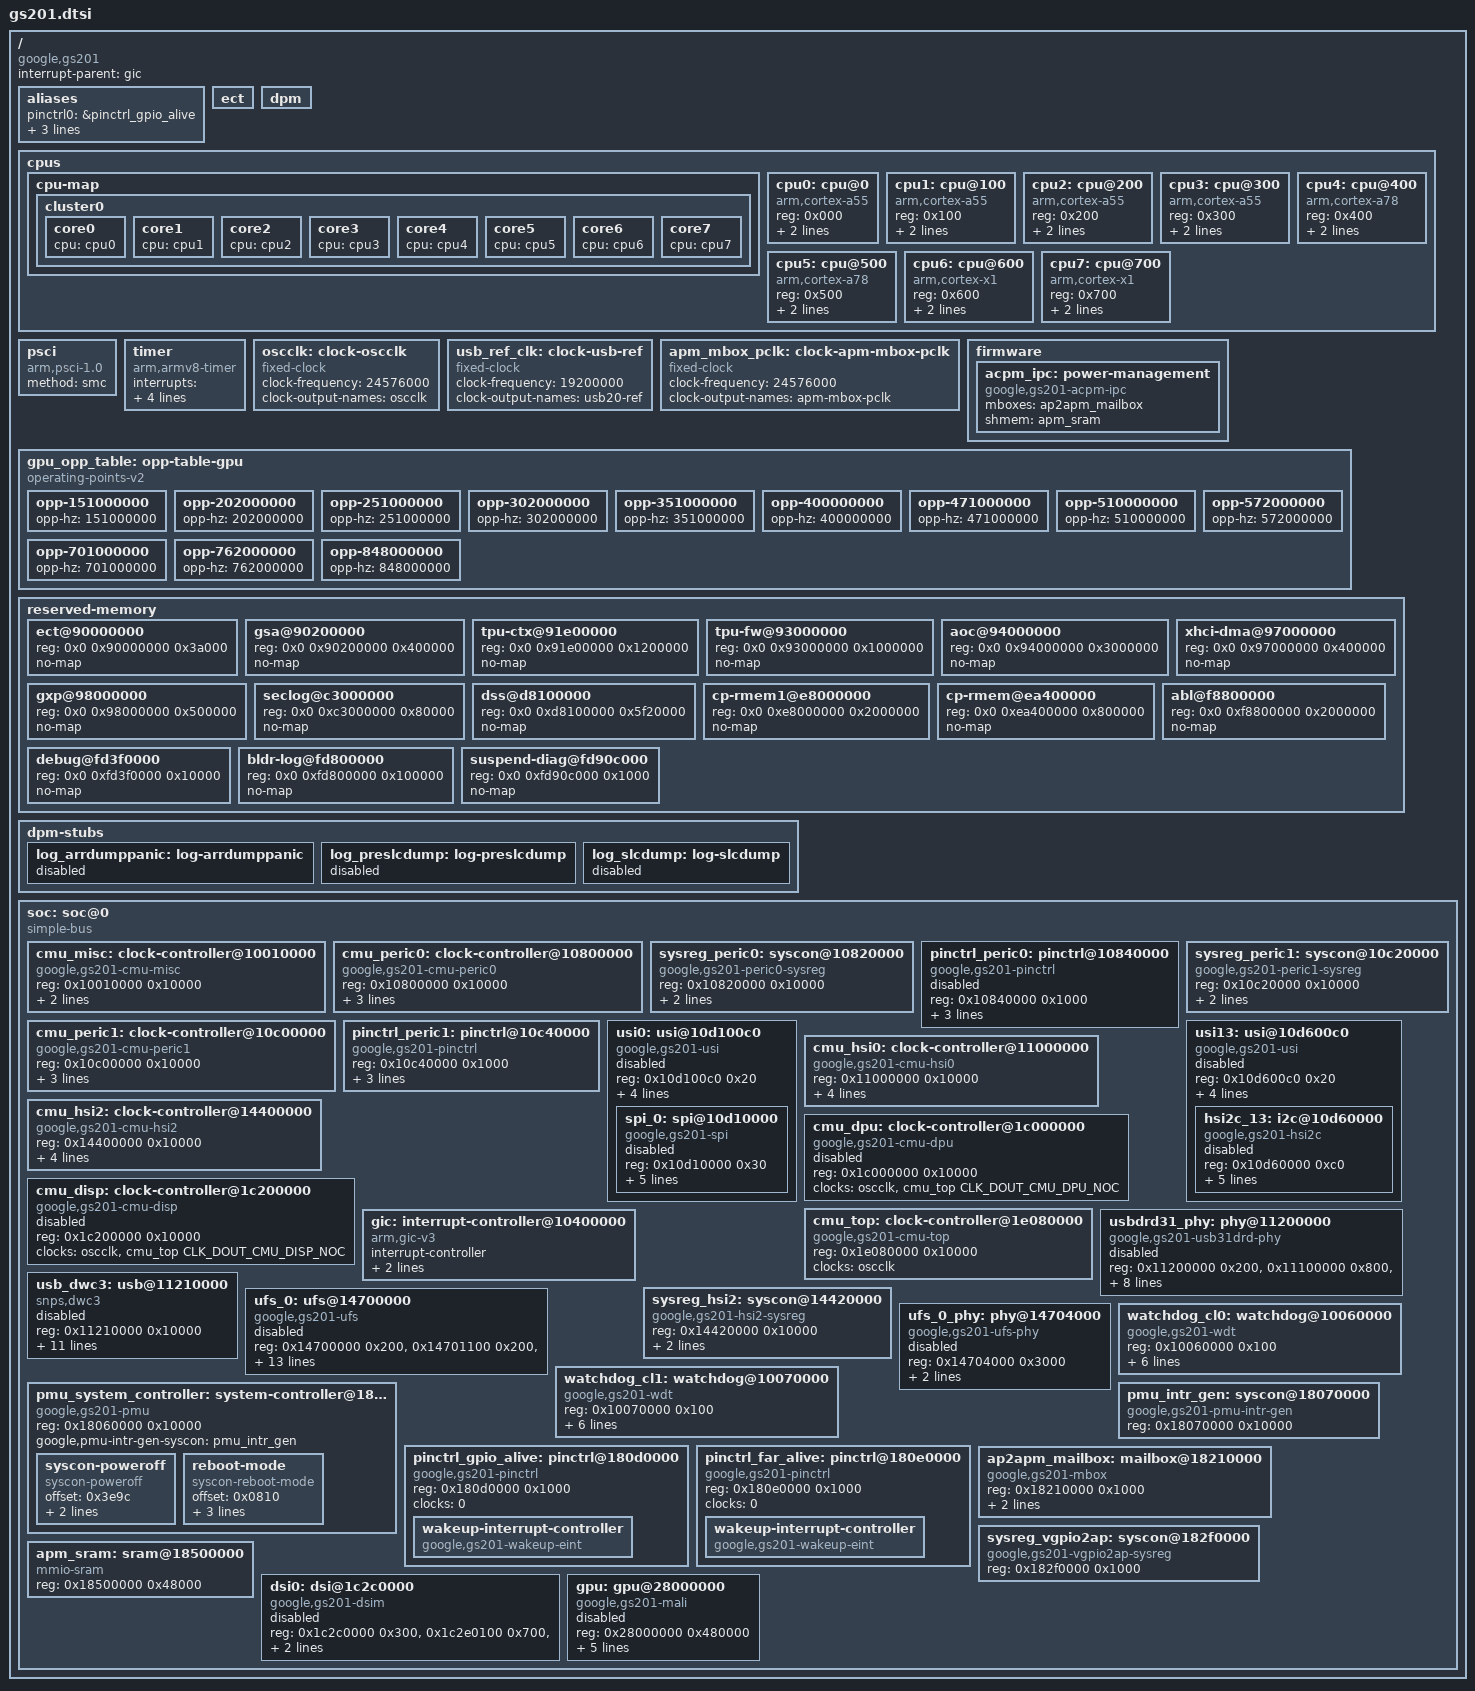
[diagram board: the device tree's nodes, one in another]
// SPDX-License-Identifier: GPL-2.0-only
/*
 * Google GS201 (Tensor G2) SoC - minimal description for early bring-up.
 */

#include <dt-bindings/clock/google,gs201.h>
#include <dt-bindings/clock/google,gs201-acpm.h>
#include <dt-bindings/gpio/gpio.h>
#include <dt-bindings/interrupt-controller/arm-gic.h>
#include <dt-bindings/interrupt-controller/irq.h>

/ {
	compatible = "google,gs201";
	#address-cells = <2>;
	#size-cells = <1>;
	interrupt-parent = <&gic>;

	aliases {
		pinctrl0 = &pinctrl_gpio_alive;
		pinctrl1 = &pinctrl_far_alive;
		pinctrl4 = &pinctrl_peric0;
		pinctrl5 = &pinctrl_peric1;
	};

	/* Required by the Pixel bootloader (ABL). */
	ect { };

	/* Target of the ABL-applied debug-policy (dpm partition) overlay. */
	dpm: dpm { };

	cpus {
		#address-cells = <1>;
		#size-cells = <0>;

		cpu-map {
			cluster0 {
				core0 { cpu = <&cpu0>; };
				core1 { cpu = <&cpu1>; };
				core2 { cpu = <&cpu2>; };
				core3 { cpu = <&cpu3>; };
				core4 { cpu = <&cpu4>; };
				core5 { cpu = <&cpu5>; };
				core6 { cpu = <&cpu6>; };
				core7 { cpu = <&cpu7>; };
			};
		};

		cpu0: cpu@0 {
			device_type = "cpu";
			compatible = "arm,cortex-a55";
			reg = <0x000>;
			enable-method = "psci";
			capacity-dmips-mhz = <250>;
		};
		cpu1: cpu@100 {
			device_type = "cpu";
			compatible = "arm,cortex-a55";
			reg = <0x100>;
			enable-method = "psci";
			capacity-dmips-mhz = <250>;
		};
		cpu2: cpu@200 {
			device_type = "cpu";
			compatible = "arm,cortex-a55";
			reg = <0x200>;
			enable-method = "psci";
			capacity-dmips-mhz = <250>;
		};
		cpu3: cpu@300 {
			device_type = "cpu";
			compatible = "arm,cortex-a55";
			reg = <0x300>;
			enable-method = "psci";
			capacity-dmips-mhz = <250>;
		};
		cpu4: cpu@400 {
			device_type = "cpu";
			compatible = "arm,cortex-a78";
			reg = <0x400>;
			enable-method = "psci";
			capacity-dmips-mhz = <927>;
		};
		cpu5: cpu@500 {
			device_type = "cpu";
			compatible = "arm,cortex-a78";
			reg = <0x500>;
			enable-method = "psci";
			capacity-dmips-mhz = <927>;
		};
		cpu6: cpu@600 {
			device_type = "cpu";
			compatible = "arm,cortex-x1";
			reg = <0x600>;
			enable-method = "psci";
			capacity-dmips-mhz = <1024>;
		};
		cpu7: cpu@700 {
			device_type = "cpu";
			compatible = "arm,cortex-x1";
			reg = <0x700>;
			enable-method = "psci";
			capacity-dmips-mhz = <1024>;
		};
	};

	psci {
		compatible = "arm,psci-1.0";
		method = "smc";
	};

	timer {
		compatible = "arm,armv8-timer";
		interrupts = <GIC_PPI 13 (GIC_CPU_MASK_SIMPLE(8) | IRQ_TYPE_LEVEL_LOW)>,
			     <GIC_PPI 14 (GIC_CPU_MASK_SIMPLE(8) | IRQ_TYPE_LEVEL_LOW)>,
			     <GIC_PPI 11 (GIC_CPU_MASK_SIMPLE(8) | IRQ_TYPE_LEVEL_LOW)>,
			     <GIC_PPI 10 (GIC_CPU_MASK_SIMPLE(8) | IRQ_TYPE_LEVEL_LOW)>;
	};

	oscclk: clock-oscclk {
		compatible = "fixed-clock";
		#clock-cells = <0>;
		clock-frequency = <24576000>;
		clock-output-names = "oscclk";
	};

	/*
	 * Bring-up placeholder: HSI0 clocks are left running by ABL (it does
	 * USB fastboot). Replace with cmu_hsi0 once clk-gs201 exists.
	 */
	usb_ref_clk: clock-usb-ref {
		compatible = "fixed-clock";
		#clock-cells = <0>;
		clock-frequency = <19200000>;	/* Google: phy_ref_clock */
		clock-output-names = "usb20-ref";
	};

	/*
	 * Bring-up placeholder for the CMU_APM gate of the AP-APM mailbox
	 * (GOUT_BLK_APM_UID_MAILBOX_APM_AP_IPCLKPORT_PCLK, CMU_APM + 0x20d4).
	 * Google's ACPM driver never touches it: the gate runs under automatic
	 * clock gating (Q-channel MAILBOX_APM_AP_QCH). Replace with cmu_apm once
	 * there is a driver for it. The rate is not used.
	 */
	apm_mbox_pclk: clock-apm-mbox-pclk {
		compatible = "fixed-clock";
		#clock-cells = <0>;
		clock-frequency = <24576000>;
		clock-output-names = "apm-mbox-pclk";
	};

	firmware {
		acpm_ipc: power-management {
			compatible = "google,gs201-acpm-ipc";
			#clock-cells = <1>;
			mboxes = <&ap2apm_mailbox>;
			shmem = <&apm_sram>;
		};
	};

	/*
	 * GPU operating points, as shader (G3D) rates: the ACPM "gpu" clock
	 * moves the top/L2 domain (G3DL2) to the level paired with each one.
	 * 202-848 MHz are Google's gs201 GPU table (gpu_dvfs_table_v1);
	 * 151 MHz is the ECT boot and resume level of both domains. No
	 * opp-microvolt: ACPM sets the rail voltages from the fused ASV tables.
	 */
	gpu_opp_table: opp-table-gpu {
		compatible = "operating-points-v2";

		opp-151000000 {
			opp-hz = /bits/ 64 <151000000>;
		};

		opp-202000000 {
			opp-hz = /bits/ 64 <202000000>;
		};

		opp-251000000 {
			opp-hz = /bits/ 64 <251000000>;
		};

		opp-302000000 {
			opp-hz = /bits/ 64 <302000000>;
		};

		opp-351000000 {
			opp-hz = /bits/ 64 <351000000>;
		};

		opp-400000000 {
			opp-hz = /bits/ 64 <400000000>;
		};

		opp-471000000 {
			opp-hz = /bits/ 64 <471000000>;
		};

		opp-510000000 {
			opp-hz = /bits/ 64 <510000000>;
		};

		opp-572000000 {
			opp-hz = /bits/ 64 <572000000>;
		};

		opp-701000000 {
			opp-hz = /bits/ 64 <701000000>;
		};

		opp-762000000 {
			opp-hz = /bits/ 64 <762000000>;
		};

		opp-848000000 {
			opp-hz = /bits/ 64 <848000000>;
		};
	};

	reserved-memory {
		#address-cells = <2>;
		#size-cells = <1>;
		ranges;

		/*
		 * Regions the stock firmware and Android keep out of the kernel's
		 * hands. seclog is written by the secure world while Linux runs;
		 * the modem and AoC regions are DMA targets once those cores run;
		 * ect holds the bootloader's clock tables. Left as System RAM they
		 * can be handed out and overwritten under us.
		 */
		ect@90000000 { reg = <0x0 0x90000000 0x3a000>; no-map; };
		gsa@90200000 { reg = <0x0 0x90200000 0x400000>; no-map; };
		tpu-ctx@91e00000 { reg = <0x0 0x91e00000 0x1200000>; no-map; };
		tpu-fw@93000000 { reg = <0x0 0x93000000 0x1000000>; no-map; };
		aoc@94000000 { reg = <0x0 0x94000000 0x3000000>; no-map; };
		xhci-dma@97000000 { reg = <0x0 0x97000000 0x400000>; no-map; };
		gxp@98000000 { reg = <0x0 0x98000000 0x500000>; no-map; };
		seclog@c3000000 { reg = <0x0 0xc3000000 0x80000>; no-map; };
		dss@d8100000 { reg = <0x0 0xd8100000 0x5f20000>; no-map; };
		cp-rmem1@e8000000 { reg = <0x0 0xe8000000 0x2000000>; no-map; };
		cp-rmem@ea400000 { reg = <0x0 0xea400000 0x800000>; no-map; };
		abl@f8800000 { reg = <0x0 0xf8800000 0x2000000>; no-map; };
		debug@fd3f0000 { reg = <0x0 0xfd3f0000 0x10000>; no-map; };
		bldr-log@fd800000 { reg = <0x0 0xfd800000 0x100000>; no-map; };
		suspend-diag@fd90c000 { reg = <0x0 0xfd90c000 0x1000>; no-map; };
	};

	/* Label stubs so the ABL "dpm" overlay applies (it only sets status). */
	dpm-stubs {
		log_arrdumppanic: log-arrdumppanic { status = "disabled"; };
		log_preslcdump: log-preslcdump { status = "disabled"; };
		log_slcdump: log-slcdump { status = "disabled"; };
	};

	soc: soc@0 {
		compatible = "simple-bus";
		#address-cells = <1>;
		#size-cells = <1>;
		ranges = <0x0 0x0 0x0 0x40000000>;

		/*
		 * Clock controllers. Consumers below still use the fixed-clock
		 * placeholders (and we boot with clk_ignore_unused); switch them
		 * one at a time:
		 *   MCT:            <&cmu_misc CLK_GOUT_MISC_MCT_PCLK>
		 *   usbdrd31_phy:   CLK_GOUT_HSI0_USB31DRD_ACLK_PHYCTRL ("phy"),
		 *                   CLK_GOUT_HSI0_USB31DRD_I_USB20_PHY_REFCLK_26 ("ref"),
		 *                   CLK_GOUT_HSI0_UASC_HSI0_CTRL_{ACLK,PCLK},
		 *                   CLK_GOUT_HSI0_USB31DRD_I_USBDPPHY_SCL_APB_PCLK
		 *   usb (dwc3):     CLK_GOUT_HSI0_USB31DRD_BUS_CLK_EARLY,
		 *                   CLK_GOUT_HSI0_USB31DRD_I_USB31DRD_SUSPEND_CLK_26,
		 *                   CLK_GOUT_HSI0_UASC_HSI0_LINK_{ACLK,PCLK},
		 *                   CLK_GOUT_HSI0_USB31DRD_I_USB31DRD_REF_CLK_40
		 */
		cmu_misc: clock-controller@10010000 {
			compatible = "google,gs201-cmu-misc";
			reg = <0x10010000 0x10000>;
			#clock-cells = <1>;
			clocks = <&cmu_top CLK_DOUT_CMU_MISC_NOC>,
				 <&cmu_top CLK_DOUT_CMU_MISC_SSS>;
			clock-names = "bus", "sss";
		};

		cmu_peric0: clock-controller@10800000 {
			compatible = "google,gs201-cmu-peric0";
			reg = <0x10800000 0x10000>;
			#clock-cells = <1>;
			clocks = <&oscclk>,
				 <&cmu_top CLK_DOUT_CMU_PERIC0_NOC>,
				 <&cmu_top CLK_DOUT_CMU_PERIC0_IP>;
			clock-names = "oscclk", "bus", "ip";
		};

		sysreg_peric0: syscon@10820000 {
			compatible = "google,gs201-peric0-sysreg", "syscon";
			reg = <0x10820000 0x10000>;
			clocks = <&cmu_peric0 CLK_GOUT_PERIC0_SYSREG_PERIC0_PCLK>;
		};

		/*
		 * Off by default: only Bluetooth (BT_REG_ON, BT_DEV_WAKE on gpp16)
		 * and the haptics I2C bus (gpp16-0/1) use it so far, and both are
		 * still at bring-up.
		 */
		pinctrl_peric0: pinctrl@10840000 {
			compatible = "google,gs201-pinctrl";
			reg = <0x10840000 0x1000>;
			clocks = <&cmu_peric0 CLK_GOUT_PERIC0_GPIO_PERIC0_PCLK>;
			clock-names = "pclk";
			interrupts = <GIC_SPI 664 IRQ_TYPE_LEVEL_HIGH>;
			status = "disabled";
		};

		cmu_peric1: clock-controller@10c00000 {
			compatible = "google,gs201-cmu-peric1";
			reg = <0x10c00000 0x10000>;
			#clock-cells = <1>;
			clocks = <&oscclk>,
				 <&cmu_top CLK_DOUT_CMU_PERIC1_NOC>,
				 <&cmu_top CLK_DOUT_CMU_PERIC1_IP>;
			clock-names = "oscclk", "bus", "ip";
		};

		sysreg_peric1: syscon@10c20000 {
			compatible = "google,gs201-peric1-sysreg", "syscon";
			reg = <0x10c20000 0x10000>;
			clocks = <&cmu_peric1 CLK_GOUT_PERIC1_SYSREG_PERIC1_PCLK>;
		};

		pinctrl_peric1: pinctrl@10c40000 {
			compatible = "google,gs201-pinctrl";
			reg = <0x10c40000 0x1000>;
			clocks = <&cmu_peric1 CLK_GOUT_PERIC1_GPIO_PERIC1_PCLK>;
			clock-names = "pclk";
			interrupts = <GIC_SPI 683 IRQ_TYPE_LEVEL_HIGH>;
		};

		usi0: usi@10d100c0 {
			compatible = "google,gs201-usi", "samsung,exynos850-usi";
			reg = <0x10d100c0 0x20>;
			ranges;
			#address-cells = <1>;
			#size-cells = <1>;
			clocks = <&cmu_peric1 CLK_GOUT_PERIC1_USI0_USI_PCLK>,
				 <&cmu_peric1 CLK_GOUT_PERIC1_USI0_USI_IPCLK>;
			clock-names = "pclk", "ipclk";
			samsung,sysreg = <&sysreg_peric1 0x1000>;
			status = "disabled";

			spi_0: spi@10d10000 {
				compatible = "google,gs201-spi", "google,gs101-spi";
				reg = <0x10d10000 0x30>;
				#address-cells = <1>;
				#size-cells = <0>;
				clocks = <&cmu_peric1 CLK_GOUT_PERIC1_USI0_USI_PCLK>,
					 <&cmu_peric1 CLK_GOUT_PERIC1_USI0_USI_IPCLK>;
				clock-names = "spi", "spi_busclk0";
				interrupts = <GIC_SPI 690 IRQ_TYPE_LEVEL_HIGH>;
				pinctrl-0 = <&spi0_bus &spi0_miso>;
				pinctrl-names = "default";
				status = "disabled";
			};
		};

		usi13: usi@10d600c0 {
			compatible = "google,gs201-usi", "samsung,exynos850-usi";
			reg = <0x10d600c0 0x20>;
			ranges;
			#address-cells = <1>;
			#size-cells = <1>;
			clocks = <&cmu_peric1 CLK_GOUT_PERIC1_USI13_USI_PCLK>,
				 <&cmu_peric1 CLK_GOUT_PERIC1_USI13_USI_IPCLK>;
			clock-names = "pclk", "ipclk";
			samsung,sysreg = <&sysreg_peric1 0x1014>;
			status = "disabled";

			hsi2c_13: i2c@10d60000 {
				compatible = "google,gs201-hsi2c",
					     "samsung,exynosautov9-hsi2c";
				reg = <0x10d60000 0xc0>;
				#address-cells = <1>;
				#size-cells = <0>;
				clocks = <&cmu_peric1 CLK_GOUT_PERIC1_USI13_USI_IPCLK>,
					 <&cmu_peric1 CLK_GOUT_PERIC1_USI13_USI_PCLK>;
				clock-names = "hsi2c", "hsi2c_pclk";
				interrupts = <GIC_SPI 695 IRQ_TYPE_LEVEL_HIGH>;
				pinctrl-0 = <&hsi2c13_bus>;
				pinctrl-names = "default";
				status = "disabled";
			};
		};

		cmu_hsi0: clock-controller@11000000 {
			compatible = "google,gs201-cmu-hsi0";
			reg = <0x11000000 0x10000>;
			#clock-cells = <1>;
			clocks = <&oscclk>,
				 <&cmu_top CLK_DOUT_CMU_HSI0_NOC>,
				 <&cmu_top CLK_DOUT_CMU_HSI0_DPGTC>,
				 <&cmu_top CLK_DOUT_CMU_HSI0_USB31DRD>,
				 <&cmu_top CLK_DOUT_CMU_HSI0_USBDPDBG>;
			clock-names = "oscclk", "bus", "dpgtc", "usb31drd",
				      "usbdpdbg";
		};

		cmu_hsi2: clock-controller@14400000 {
			compatible = "google,gs201-cmu-hsi2";
			reg = <0x14400000 0x10000>;
			#clock-cells = <1>;
			clocks = <&oscclk>,
				 <&cmu_top CLK_DOUT_CMU_HSI2_NOC>,
				 <&cmu_top CLK_DOUT_CMU_HSI2_PCIE>,
				 <&cmu_top CLK_DOUT_CMU_HSI2_UFS_EMBD>,
				 <&cmu_top CLK_DOUT_CMU_HSI2_MMC_CARD>;
			clock-names = "oscclk", "bus", "pcie", "ufs", "mmc";
		};

		/*
		 * The display CMUs are left disabled until a display driver
		 * needs them: the bootloader keeps their power domains (pd_dpu,
		 * pd_disp) on, and registering them switches the CMUs to
		 * automatic clock gating under a running scanout.
		 */
		cmu_dpu: clock-controller@1c000000 {
			compatible = "google,gs201-cmu-dpu";
			reg = <0x1c000000 0x10000>;
			#clock-cells = <1>;
			clocks = <&oscclk>, <&cmu_top CLK_DOUT_CMU_DPU_NOC>;
			clock-names = "oscclk", "bus";
			status = "disabled";
		};

		cmu_disp: clock-controller@1c200000 {
			compatible = "google,gs201-cmu-disp";
			reg = <0x1c200000 0x10000>;
			#clock-cells = <1>;
			clocks = <&oscclk>, <&cmu_top CLK_DOUT_CMU_DISP_NOC>;
			clock-names = "oscclk", "bus";
			status = "disabled";
		};

		cmu_top: clock-controller@1e080000 {
			compatible = "google,gs201-cmu-top";
			reg = <0x1e080000 0x10000>;
			#clock-cells = <1>;
			clocks = <&oscclk>;
			clock-names = "oscclk";
		};

		gic: interrupt-controller@10400000 {
			compatible = "arm,gic-v3";
			#interrupt-cells = <3>;
			#address-cells = <0>;
			interrupt-controller;
			reg = <0x10400000 0x10000>,	/* GICD */
			      <0x10440000 0x100000>;	/* GICR x8 */
			interrupts = <GIC_PPI 9 IRQ_TYPE_LEVEL_HIGH>;
		};

		usbdrd31_phy: phy@11200000 {
			compatible = "google,gs201-usb31drd-phy";
			reg = <0x11200000 0x200>,
			      <0x11100000 0x800>,
			      <0x110f0000 0x2800>;
			reg-names = "phy", "pcs", "pma";
			clocks = <&cmu_hsi0 CLK_GOUT_HSI0_USB31DRD_ACLK_PHYCTRL>,
				 <&cmu_hsi0 CLK_GOUT_HSI0_USB31DRD_I_USB20_PHY_REFCLK_26>,
				 <&cmu_hsi0 CLK_GOUT_HSI0_UASC_HSI0_CTRL_ACLK>,
				 <&cmu_hsi0 CLK_GOUT_HSI0_UASC_HSI0_CTRL_PCLK>,
				 <&cmu_hsi0 CLK_GOUT_HSI0_USB31DRD_I_USBDPPHY_SCL_APB_PCLK>;
			clock-names = "phy", "ref", "ctrl_aclk", "ctrl_pclk",
				      "scl_pclk";
			samsung,pmu-syscon = <&pmu_system_controller>;
			#phy-cells = <1>;
			status = "disabled";
		};

		usb_dwc3: usb@11210000 {
			compatible = "snps,dwc3";
			reg = <0x11210000 0x10000>;
			interrupts = <GIC_SPI 379 IRQ_TYPE_LEVEL_HIGH>;
			clocks = <&cmu_hsi0 CLK_GOUT_HSI0_USB31DRD_I_USB31DRD_REF_CLK_40>,
				 <&cmu_hsi0 CLK_GOUT_HSI0_USB31DRD_BUS_CLK_EARLY>,
				 <&cmu_hsi0 CLK_GOUT_HSI0_USB31DRD_I_USB31DRD_SUSPEND_CLK_26>;
			clock-names = "ref", "bus_early", "suspend";
			phys = <&usbdrd31_phy 0>;
			phy-names = "usb2-phy";
			dr_mode = "peripheral";
			maximum-speed = "high-speed";
			snps,dis_u2_susphy_quirk;
			snps,dis_u3_susphy_quirk;
			snps,has-lpm-erratum;
			status = "disabled";
		};

		sysreg_hsi2: syscon@14420000 {
			compatible = "google,gs201-hsi2-sysreg", "syscon";
			reg = <0x14420000 0x10000>;
			clocks = <&cmu_hsi2 CLK_GOUT_HSI2_SYSREG_HSI2_PCLK>;
		};

		/*
		 * No gs201 pinctrl driver yet: the UFS reset (gph3-1) and
		 * reference clock output (gph3-0) pins on the HSI2UFS pin
		 * controller are left in their UFS function by the bootloader.
		 */
		ufs_0: ufs@14700000 {
			compatible = "google,gs201-ufs";
			reg = <0x14700000 0x200>,
			      <0x14701100 0x200>,
			      <0x14780000 0xa000>,
			      <0x14600000 0x100>;
			reg-names = "hci", "vs_hci", "unipro", "ufsp";
			interrupts = <GIC_SPI 453 IRQ_TYPE_LEVEL_HIGH>;
			clocks = <&cmu_hsi2 CLK_GOUT_HSI2_UFS_EMBD_I_ACLK>,
				 <&cmu_hsi2 CLK_GOUT_HSI2_UFS_EMBD_I_CLK_UNIPRO>,
				 <&cmu_hsi2 CLK_GOUT_HSI2_UFS_EMBD_I_FMP_CLK>,
				 <&cmu_hsi2 CLK_GOUT_HSI2_QE_UFS_EMBD_HSI2_ACLK>,
				 <&cmu_hsi2 CLK_GOUT_HSI2_QE_UFS_EMBD_HSI2_PCLK>,
				 <&cmu_hsi2 CLK_GOUT_HSI2_SYSREG_HSI2_PCLK>;
			clock-names = "core_clk", "sclk_unipro_main", "fmp",
				      "aclk", "pclk", "sysreg";
			dma-coherent;
			freq-table-hz = <0 0>, <0 0>, <0 0>, <0 0>, <0 0>, <0 0>;
			phys = <&ufs_0_phy>;
			phy-names = "ufs-phy";
			samsung,sysreg = <&sysreg_hsi2 0x710>;
			status = "disabled";
		};

		ufs_0_phy: phy@14704000 {
			compatible = "google,gs201-ufs-phy";
			reg = <0x14704000 0x3000>;
			reg-names = "phy-pma";
			samsung,pmu-syscon = <&pmu_system_controller>;
			#phy-cells = <0>;
			clocks = <&oscclk>;
			clock-names = "ref_clk";
			status = "disabled";
		};

		/*
		 * ABL leaves both watchdogs running (about 60 s). The driver stops
		 * them at probe unless tmr_atboot is set.
		 */
		watchdog_cl0: watchdog@10060000 {
			compatible = "google,gs201-wdt";
			reg = <0x10060000 0x100>;
			clocks = <&cmu_misc CLK_GOUT_MISC_WDT_CLUSTER0_PCLK>,
				 <&oscclk>;
			clock-names = "watchdog", "watchdog_src";
			interrupts = <GIC_SPI 797 IRQ_TYPE_LEVEL_HIGH>;
			samsung,syscon-phandle = <&pmu_system_controller>;
			samsung,cluster-index = <0>;
		};

		watchdog_cl1: watchdog@10070000 {
			compatible = "google,gs201-wdt";
			reg = <0x10070000 0x100>;
			clocks = <&cmu_misc CLK_GOUT_MISC_WDT_CLUSTER1_PCLK>,
				 <&oscclk>;
			clock-names = "watchdog", "watchdog_src";
			interrupts = <GIC_SPI 798 IRQ_TYPE_LEVEL_HIGH>;
			samsung,syscon-phandle = <&pmu_system_controller>;
			samsung,cluster-index = <1>;
		};

		pmu_system_controller: system-controller@18060000 {
			compatible = "google,gs201-pmu", "syscon";
			reg = <0x18060000 0x10000>;
			google,pmu-intr-gen-syscon = <&pmu_intr_gen>;

			syscon-poweroff {
				compatible = "syscon-poweroff";
				offset = <0x3e9c>;	/* PAD_CTRL_PWR_HOLD */
				mask = <0x100>;
				value = <0x0>;
			};

			reboot-mode {
				compatible = "syscon-reboot-mode";
				offset = <0x0810>;	/* SYSIP_DAT0 */
				mode-bootloader = <0xfc>;
				mode-fastboot = <0xfa>;
				mode-recovery = <0xff>;
			};
		};

		pmu_intr_gen: syscon@18070000 {
			compatible = "google,gs201-pmu-intr-gen", "syscon";
			reg = <0x18070000 0x10000>;
		};

		pinctrl_gpio_alive: pinctrl@180d0000 {
			compatible = "google,gs201-pinctrl";
			reg = <0x180d0000 0x1000>;
			/* TODO: CMU_APM gate, once there is a driver for it */
			clocks = <0>;
			clock-names = "pclk";

			wakeup-interrupt-controller {
				compatible = "google,gs201-wakeup-eint",
					     "google,gs101-wakeup-eint",
					     "samsung,exynos850-wakeup-eint",
					     "samsung,exynos7-wakeup-eint";
			};
		};

		pinctrl_far_alive: pinctrl@180e0000 {
			compatible = "google,gs201-pinctrl";
			reg = <0x180e0000 0x1000>;
			/* TODO: CMU_APM gate, once there is a driver for it */
			clocks = <0>;
			clock-names = "pclk";

			wakeup-interrupt-controller {
				compatible = "google,gs201-wakeup-eint",
					     "google,gs101-wakeup-eint",
					     "samsung,exynos850-wakeup-eint",
					     "samsung,exynos7-wakeup-eint";
			};
		};

		ap2apm_mailbox: mailbox@18210000 {
			compatible = "google,gs201-mbox", "google,gs101-mbox";
			reg = <0x18210000 0x1000>;
			clocks = <&apm_mbox_pclk>;
			clock-names = "pclk";
			interrupts = <GIC_SPI 78 IRQ_TYPE_LEVEL_HIGH>;
			#mbox-cells = <0>;
		};

		/* Latches the S2MPG12 PMIC's in-band interrupt (GIC SPI 72). */
		sysreg_vgpio2ap: syscon@182f0000 {
			compatible = "google,gs201-vgpio2ap-sysreg", "syscon";
			reg = <0x182f0000 0x1000>;
		};

		apm_sram: sram@18500000 {
			compatible = "mmio-sram";
			reg = <0x18500000 0x48000>;
			#address-cells = <1>;
			#size-cells = <1>;
			ranges = <0x0 0x18500000 0x48000>;
		};

		/*
		 * No power-domains: the bootloader leaves both G3D power domains
		 * (pd_g3d, pd_embedded_g3d) on, and nothing in Linux turns them
		 * off yet. Their on/off sequence needs EL3 calls that the generic
		 * Exynos power domain driver does not make.
		 */
		dsi0: dsi@1c2c0000 {
			compatible = "google,gs201-dsim";
			reg = <0x1c2c0000 0x300>,
			      <0x1c2e0100 0x700>,
			      <0x1c2e0000 0x100>;
			reg-names = "dsi", "dphy", "dphy-extra";
			interrupts = <GIC_SPI 250 IRQ_TYPE_LEVEL_HIGH>;
			#address-cells = <1>;
			#size-cells = <0>;
			status = "disabled";
		};

		gpu: gpu@28000000 {
			compatible = "google,gs201-mali", "arm,mali-valhall-csf";
			reg = <0x28000000 0x480000>;
			interrupts = <GIC_SPI 329 IRQ_TYPE_LEVEL_HIGH>,
				     <GIC_SPI 330 IRQ_TYPE_LEVEL_HIGH>,
				     <GIC_SPI 328 IRQ_TYPE_LEVEL_HIGH>;
			interrupt-names = "job", "mmu", "gpu";
			clocks = <&acpm_ipc GS201_CLK_ACPM_GPU>;
			clock-names = "core";
			operating-points-v2 = <&gpu_opp_table>;
			status = "disabled";
		};
	};
};

#include "gs201-pinctrl.dtsi"
